# Cortex_M52 register map
Vendor: Arm Ltd.; Series: ARMv8.1-M Mainline; File version: 1.0.0
CPU: other r0p0, little endian, MPU, FPU, double-precision FPU, DSP, 8 interrupt priority bits
Registers are 32-bit, read-write, reset 0x0 unless marked. A register's access mark holds for its fields unless they carry their own. Offsets are from the block's base; [hi:lo] are bit positions.

## DCB — Debug Control Block: halting debug control and status (DHCSR), core register access from the debugger (DCRSR/DCRDR), vector catch, the DebugMonitor exception and trace enable (DEMCR), and on ARMv8-M debug authentication and security control.
Base 0xE000EDF0
Same registers: DCB_NS 0xE002EDF0
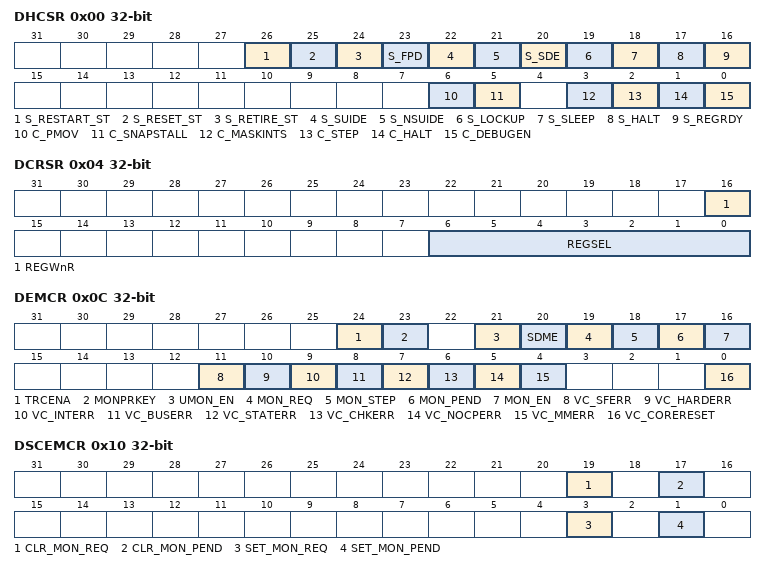
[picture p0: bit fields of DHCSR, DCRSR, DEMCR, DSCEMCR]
0x00 DHCSR — Debug Halting Control and Status Register: debugger enable, halt, step and interrupt masking (writes need 0xA05F in bits [31:16], DBGKEY), and read-only processor status (halted, sleeping, locked up, reset since last read) in the same upper bits.
  [26] S_RESTART_ST ro — Sticky: the processor left Debug state (restarted) since the last read (ARMv8-M). Cleared on read.
  [25] S_RESET_ST ro — Sticky: the processor was reset since the last read of DHCSR. Cleared on read.
  [24] S_RETIRE_ST ro — Sticky: at least one instruction retired since the last read of DHCSR. Cleared on read.
  [23] S_FPD ro — Floating-point debuggable: 0 = the FP/MVE registers are not accessible to the debugger (unit powered down or Secure-only). Read-only (ARMv8.1-M).
  [22] S_SUIDE ro — Secure unprivileged invasive debug enabled (ARMv8.1-M UDE). Read-only.
  [21] S_NSUIDE ro — Non-secure unprivileged invasive debug enabled (ARMv8.1-M UDE). Read-only.
  [20] S_SDE ro — Secure debug enabled: 1 = halting debug is permitted in Secure state (DAUTHSTATUS.SID). Read-only.
  [19] S_LOCKUP ro — Processor is in lockup state - a fault occurred at priority -1 or in NMI/HardFault with no way to escalate; PC reads 0xFFFFFFFE. Read-only.
  [18] S_SLEEP ro — Processor is sleeping (WFI, WFE or sleep-on-exit). Read-only.
  [17] S_HALT ro — Processor is in Debug state (halted). Read-only.
  [16] S_REGRDY ro — Register transfer complete: a DCRSR read/write has finished and DCRDR is valid. Read-only.
  [6] C_PMOV — Halt on PMU overflow (ARMv8.1-M): 1 = a PMU counter overflow generates a halt debug event (DFSR.PMU).
  [5] C_SNAPSTALL — 1 = force the processor out of a stalled load/store (bus never responded). The instruction is abandoned, not restarted - the state afterwards is unpredictable; a reset is usually needed.
  [3] C_MASKINTS — Mask PendSV, SysTick and IRQ (not NMI/faults) while stepping, so a step does not enter an interrupt handler. Change only while halted, together with C_HALT.
  [2] C_STEP — Single step: 1 = when leaving Debug state, execute one instruction and halt again.
  [1] C_HALT — Halt request: 1 = halt the processor (Debug state); 0 = run. Needs C_DEBUGEN = 1.
  [0] C_DEBUGEN — Halting debug enable. Set by the debugger; cannot be set by software. While 0 the other C_* bits are ignored and BKPT with no monitor escalates to HardFault.
0x04 DCRSR wo — Debug Core Register Selector Register: with the processor halted, selects a core register to transfer to or from DCRDR. Poll DHCSR.S_REGRDY for completion.
  [16] REGWnR — Direction: 0 = read the selected register into DCRDR, 1 = write DCRDR to the selected register.
  [6:0] REGSEL — Register to transfer: 0-12 R0-R12, 13 SP (current), 14 LR, 15 DebugReturnAddress (PC), 16 xPSR, 17 MSP, 18 PSP, 20 packed CONTROL[31:24] FAULTMASK[16] BASEPRI[8] PRIMASK[0], 33 FPSCR, 64-95 S0-S31; ARMv8-M: 24 MSP_NS, 25 PSP_NS, 26 MSP_S, 27 PSP_S, 28 MSPLIM_S, 29 PSPLIM_S, 30 MSPLIM_NS, 31 PSPLIM_NS, 34/35 packed CONTROL/masks _S/_NS.
0x08 DCRDR — Debug Core Register Data Register: data for DCRSR transfers. Also usable as a general debugger-to-target mailbox.
  [31:0] DBGTMP — Data read from, or to be written to, the register selected by DCRSR.
0x0C DEMCR — Debug Exception and Monitor Control Register: vector catch on reset and faults, DebugMonitor exception control, and TRCENA, the global enable for DWT, ITM, ETM and TPIU.
  [24] TRCENA — Trace enable: global enable for the DWT, ITM, ETM and TPIU. Must be 1 before any DWT/ITM register is written (CYCCNT, watchpoints, SWO output).
  [23] MONPRKEY — Monitor pending request key (ARMv8.1-M): a write to MON_PEND takes effect only if this bit is written as 1 in the same access.
  [21] UMON_EN — Unprivileged monitor enable (ARMv8.1-M UDE): 1 = the DebugMonitor may be used for unprivileged debug.
  [20] SDME — Secure DebugMonitor enable: 1 = the DebugMonitor exception targets Secure state. Read-only status derived from the debug authentication signals.
  [19] MON_REQ — Monitor request semaphore: set by software to tell the monitor handler it was entered by request rather than by a debug event (not affected by hardware).
  [18] MON_STEP — Monitor step: 1 = after the monitor returns, execute one instruction and re-enter the monitor (software single-step).
  [17] MON_PEND — Set the DebugMonitor exception pending (software or debugger can use it to enter the monitor).
  [16] MON_EN — DebugMonitor exception enable: with no halting debugger attached, BKPT, FPB and DWT events raise the DebugMonitor exception (12) instead of a HardFault.
  [11] VC_SFERR — Vector catch on SecureFault entry (Security Extension).
  [10] VC_HARDERR — Vector catch on HardFault entry - with this set the core halts at the fault instead of running the HardFault handler.
  [9] VC_INTERR — Vector catch on a fault during exception entry or return (stacking/unstacking errors, INVPC on return).
  [8] VC_BUSERR — Vector catch on BusFault entry.
  [7] VC_STATERR — Vector catch on a state-error UsageFault (UNDEFINSTR, INVSTATE, INVPC).
  [6] VC_CHKERR — Vector catch on a checking-error UsageFault (UNALIGNED, DIVBYZERO).
  [5] VC_NOCPERR — Vector catch on a NOCP (no coprocessor) UsageFault.
  [4] VC_MMERR — Vector catch on MemManage fault entry.
  [0] VC_CORERESET — Vector catch on core reset: halt immediately after reset (the 'reset catch' debuggers use to stop at the first instruction). Needs C_DEBUGEN.
0x10 DSCEMCR wo — Debug Set/Clear Exception and Monitor Control Register (ARMv8.1-M): atomic set/clear access to the DEMCR MON_PEND and MON_REQ bits.
  [19] CLR_MON_REQ — Write 1 to clear DEMCR.MON_REQ.
  [17] CLR_MON_PEND — Write 1 to clear DEMCR.MON_PEND.
  [3] SET_MON_REQ — Write 1 to set DEMCR.MON_REQ.
  [1] SET_MON_PEND — Write 1 to set DEMCR.MON_PEND.
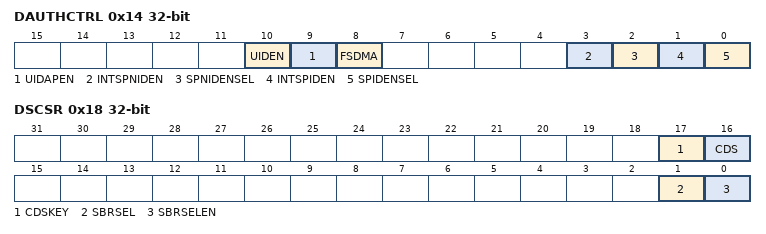
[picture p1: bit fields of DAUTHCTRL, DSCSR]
0x14 DAUTHCTRL — Debug Authentication Control Register (ARMv8-M): lets Secure software override the external SPIDEN/SPNIDEN debug authentication inputs.
  [10] UIDEN — Unprivileged invasive debug enable (ARMv8.1-M UDE): 1 = halting debug is allowed only in unprivileged code.
  [9] UIDAPEN — Unprivileged invasive debug of the DAP enable (ARMv8.1-M UDE).
  [8] FSDMA — Force Secure DebugMonitor allowed (ARMv8.1-M): 1 = the DebugMonitor is permitted in Secure state regardless of SPIDEN.
  [3] INTSPNIDEN — Internal Secure non-invasive debug enable, used when SPNIDENSEL = 1.
  [2] SPNIDENSEL — 1 = INTSPNIDEN overrides the external SPNIDEN input (Secure non-invasive debug/trace enable).
  [1] INTSPIDEN — Internal Secure invasive debug enable, used when SPIDENSEL = 1.
  [0] SPIDENSEL — 1 = INTSPIDEN overrides the external SPIDEN input (Secure invasive debug enable).
0x18 DSCSR — Debug Security Control and Status Register (ARMv8-M): the current security state of the core and which banked register set the debugger sees.
  [17] CDSKEY — CDS write key: CDS is only updated if this bit is written as 0 in the same access. Reads as 1.
  [16] CDS — Current domain Secure: 1 = the processor is in Secure state. The debugger may write it (with CDSKEY = 0) while halted to switch state.
  [1] SBRSEL — Security state of the banked registers accessed through DCRSR when SBRSELEN = 1: 0 = Non-secure, 1 = Secure.
  [0] SBRSELEN — Secure banked register select enable: 1 = SBRSEL chooses which security state's banked registers DCRSR accesses; 0 = the current state's.
